# f28p551x_i2c_regs register map
Vendor: Texas Instruments
Peripheral module from a debugger description file (folder C2000).
Address unit: 16 bits
Registers are 16-bit, read-write, no defined reset value unless marked. A register's access mark holds for its fields unless they carry their own. Offsets are as the file gives them; lines under a group give offsets from that group; [hi:lo] are bit positions; {n}, {i} and the like mark numbered series; 'fields as' and 'values as' point back to an identical list; <NAME> marks a mode.

## I2C_REGS — I2C Registers
0x00 I2COAR — I2C Own address
  [9:0] OAR
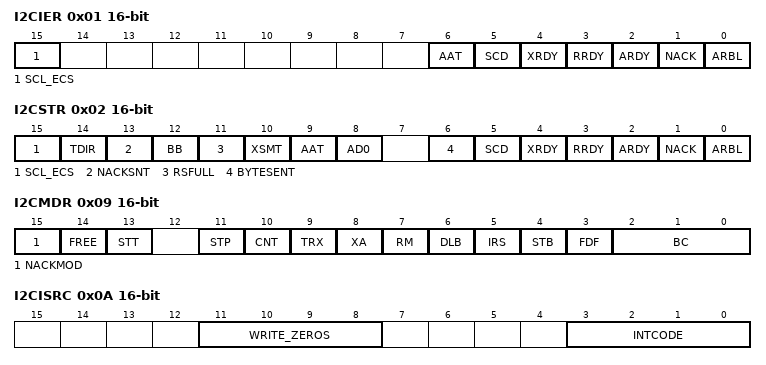
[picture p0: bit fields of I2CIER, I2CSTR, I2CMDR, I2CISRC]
0x01 I2CIER — I2C Interrupt Enable
  [15] SCL_ECS — SCL Extended Automatic Clock Stretch interrupt enable
  [6] AAT — Addressed as TARGET interrupt enable
  [5] SCD — Stop condition detected interrupt enable
  [4] XRDY — Transmit-data-ready interrupt enable
  [3] RRDY — Receive-data-ready interrupt enable
  [2] ARDY — Register-access-ready interrupt enable
  [1] NACK — No-acknowledgment interrupt enable
  [0] ARBL — Arbitration-lost interrupt enable
0x02 I2CSTR access per field — I2C Status
  [15] SCL_ECS rw — SCL Extended Automatic Clock Stretch Status
  [14] TDIR rw — TARGET direction bit
  [13] NACKSNT rw — NACK sent bit.
  [12] BB ro — Bus busy bit.
  [11] RSFULL ro — Receive shift register full bit.
  [10] XSMT ro — Transmit shift register empty bit.
  [9] AAT ro — Addressed-as-TARGET bit
  [8] AD0 ro — Address 0 bits
  [6] BYTESENT rw — Byte transmit over indication
  [5] SCD rw — Stop condition detected bit.
  [4] XRDY ro — Transmit-data-ready interrupt flag bit.
  [3] RRDY rw — Receive-data-ready interrupt flag bit.
  [2] ARDY rw — Register-access-ready interrupt flag bit
  [1] NACK rw — No-acknowledgment interrupt flag bit.
  [0] ARBL rw — Arbitration-lost interrupt flag bit
0x03 I2CCLKL — I2C Clock low-time divider
  [15:0] I2CCLKL — Clock low-time divide-down value.
0x04 I2CCLKH — I2C Clock high-time divider
  [15:0] I2CCLKH — Clock high-time divide-down value.
0x05 I2CCNT — I2C Data count
  [15:0] I2CCNT — Data count value.
0x06 I2CDRR ro — I2C Data receive
  [7:0] DATA — Receive data
0x07 I2CTAR — I2C TARGET address
  [9:0] TAR — TARGET Address
0x08 I2CDXR — I2C Data Transmit
  [7:0] DATA — Transmit data
0x09 I2CMDR — I2C Mode
  [15] NACKMOD — NACK mode bit
  [14] FREE — Debug Action
  [13] STT — START condition bit
  [11] STP — STOP Condition
  [10] CNT — CONTROLLER Mode
  [9] TRX — Transmitter Mode
  [8] XA — Expanded Address Mode
  [7] RM — Repeat Mode
  [6] DLB — Digital Loopback Mode
  [5] IRS — I2C Module Reset
  [4] STB — START Byte Mode
  [3] FDF — Free Data Format
  [2:0] BC — Bit count bits.
0x0A I2CISRC access per field — I2C Interrupt Source
  [11:8] WRITE_ZEROS rw — Always write all 0s to this field
  [3:0] INTCODE ro — Interrupt code bits.
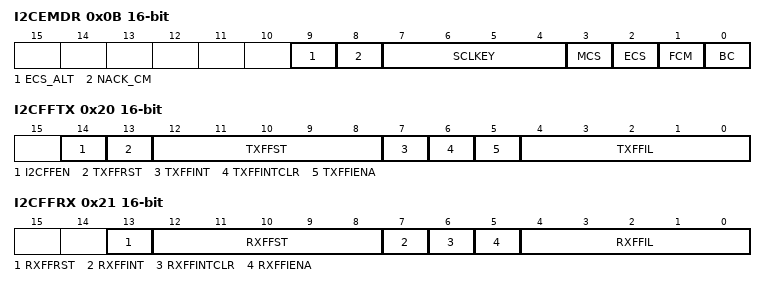
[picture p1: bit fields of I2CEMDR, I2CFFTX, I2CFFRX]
0x0B I2CEMDR — I2C Extended Mode
  [9] ECS_ALT — Alternative Extended Automatic Clock Stretching Mode
  [8] NACK_CM — NACK Compatibility Mode
  [7:4] SCLKEY — KEY
  [3] MCS — Manual Clock Stretching Mode
  [2] ECS — Extended Automatic Clock Stretching Mode
  [1] FCM — Forward Compatibility for TX behavior in Type1
  [0] BC — Backwards compatibility mode
0x0C I2CPSC — I2C Prescaler
  [7:0] IPSC — I2C Prescaler Divide Down
0x20 I2CFFTX access per field — I2C FIFO Transmit
  [14] I2CFFEN rw — Transmit FIFO Enable
  [13] TXFFRST rw — Transmit FIFO Reset
  [12:8] TXFFST ro — Transmit FIFO Status
  [7] TXFFINT ro — Transmit FIFO Interrupt Flag
  [6] TXFFINTCLR rw — Transmit FIFO Interrupt Flag Clear
  [5] TXFFIENA rw — Transmit FIFO Interrupt Enable
  [4:0] TXFFIL rw — Transmit FIFO Interrupt Level
0x21 I2CFFRX access per field — I2C FIFO Receive
  [13] RXFFRST rw — Receive FIFO Reset
  [12:8] RXFFST ro — Receive FIFO Status
  [7] RXFFINT ro — Receive FIFO Interrupt Flag
  [6] RXFFINTCLR rw — Receive FIFO Interrupt Flag Clear
  [5] RXFFIENA rw — Receive FIFO Interrupt Enable
  [4:0] RXFFIL rw — Receive FIFO Interrupt Level
